# ATSAM4LS8C device description
Architecture: CORTEX-M4; Family: SAM4; Series: SAM4L
Registers are 32-bit, read-write, reset 0x0 unless marked. A register's access mark holds for its fields unless they carry their own. Offsets are from the block's base; [hi:lo] are bit positions; {n}, {i} and the like mark numbered series; 'fields as' and 'values as' point back to an identical list.

## CHIPID — Chip ID Registers
Instances: CHIPID 0x400E0400
0x340 CIDR ro reset 0xAB0B0AE0 — Chip ID Register
0x344 EXID ro reset 0x14000002 — Chip ID Extension Register

## CRCCU — CRC Calculation Unit
Instances: CRCCU 0x400A4000
0x00 DSCR — Descriptor Base Register
  [31:9] DSCR — Description Base Address
0x08 DMAEN wo (atomic set of DMASR) — DMA Enable Register
  [0] DMAEN — DMA Enable
0x0C DMADIS wo (atomic clear of DMASR) — DMA Disable Register
  [0] DMADIS — DMA Disable
0x10 DMASR ro — DMA Status Register
  [0] DMASR — DMA Channel Status
0x14 DMAIER wo (atomic set of DMAIMR) — DMA Interrupt Enable Register
  [0] DMAIER — DMA Interrupt Enable
0x18 DMAIDR wo (atomic clear of DMAIMR) — DMA Interrupt Disable Register
  [0] DMAIDR — DMA Interrupt Disable
0x1C DMAIMR ro — DMA Interrupt Mask Register
  [0] DMAIMR — DMA Interrupt Mask
0x20 DMAISR ro — DMA Interrupt Status Register
  [0] DMAISR — DMA Interrupt Status
0x34 CR wo — Control Register
  [0] RESET — Reset CRCComputation
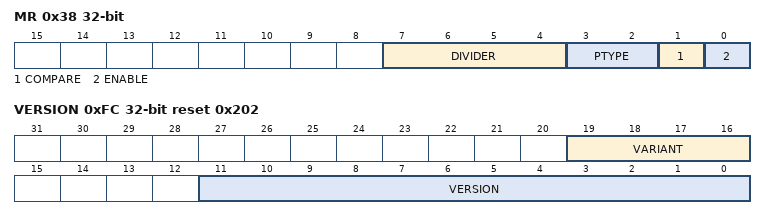
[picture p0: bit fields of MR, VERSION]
0x38 MR — Mode Register
  [7:4] DIVIDER — Bandwidth Divider
  [3:2] PTYPE — Polynomial Type
    0=CCITT8023; 1=CASTAGNOLI; 2=CCITT16
  [1] COMPARE — CRC Compare
  [0] ENABLE — CRC Computation Enable
0x3C SR ro reset 0xFFFFFFFF — Status Register
  [31:0] CRC — Cyclic Redundancy Check Value
0x40 IER wo (atomic set of IMR) — Interrupt Enable Register
  [0] ERRIER — CRC Error Interrupt Enable
0x44 IDR wo (atomic clear of IMR) — Interrupt Disable Register
  [0] ERRIDR — CRC Error Interrupt Disable
0x48 IMR ro — Interrupt Mask Register
  [0] ERRIMR — CRC Error Interrupt Mask
0x4C ISR ro — Interrupt Status Register
  [0] ERRISR — CRC Error Interrupt Status
0xFC VERSION ro reset 0x202
  [19:16] VARIANT — Variant Number
  [11:0] VERSION — Version Number

## DACC — DAC Controller
Instances: DACC 0x4003C000
0x00 CR wo — Control Register
  [0] SWRST — Software Reset
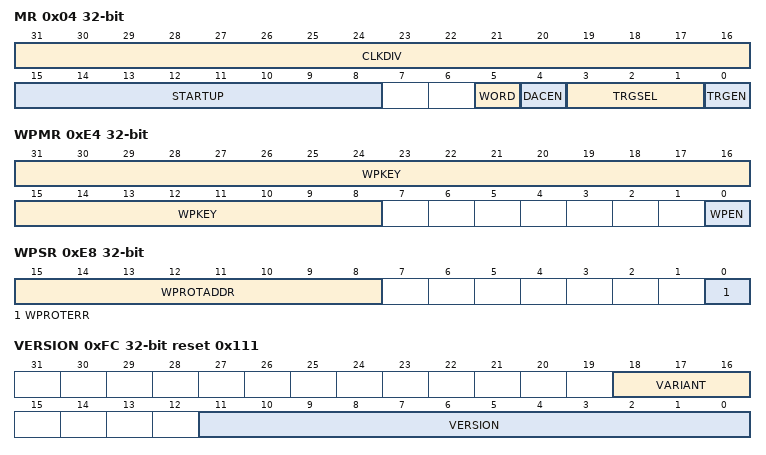
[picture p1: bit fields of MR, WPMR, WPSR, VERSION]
0x04 MR — Mode Register
  [31:16] CLKDIV — Clock Divider for Internal Trigger
  [15:8] STARTUP — Startup Time Selection
  [5] WORD — Word Transfer
  [4] DACEN — DAC Enable
  [3:1] TRGSEL — Trigger Selection
  [0] TRGEN — Trigger Enable
0x08 CDR wo — Conversion Data Register
  [31:0] DATA — Data to Convert
0x0C IER wo (atomic set of IMR) — Interrupt Enable Register
  [0] TXRDY — Transmit Ready Interrupt Enable
0x10 IDR wo reset not defined (atomic clear of IMR) — Interrupt Disable Register
  [0] TXRDY — Transmit Ready Interrupt Disable
0x14 IMR ro — Interrupt Mask Register
  [0] TXRDY — Transmit Ready Interrupt Mask
0x18 ISR ro — Interrupt Status Register
  [0] TXRDY — Transmit Ready Interrupt Status
0xE4 WPMR — Write Protect Mode Register
  [31:8] WPKEY — Write Protect Key
  [0] WPEN — Write Protect Enable
0xE8 WPSR ro — Write Protect Status Register
  [15:8] WPROTADDR — Write Protection Error Address
  [0] WPROTERR — Write Protection Error
0xFC VERSION ro reset 0x111
  [18:16] VARIANT — Variant Number
  [11:0] VERSION — Version Number

## EIC — External Interrupt Controller
Instances: EIC 0x400F1000
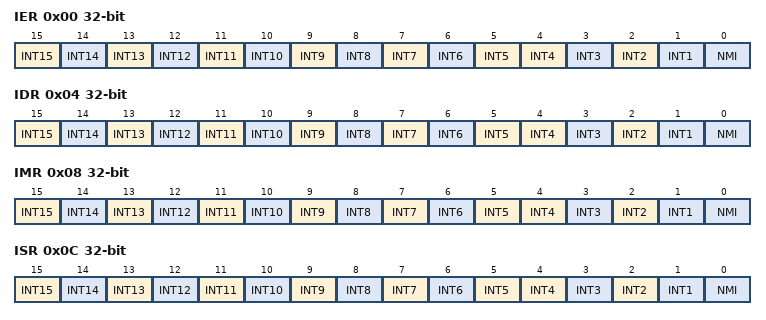
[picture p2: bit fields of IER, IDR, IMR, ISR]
0x00 IER wo (atomic set of IMR) — Interrupt Enable Register
  [n] INT{n} (n=5..15) — External Interrupt {n}
  [n] INT{n} (n=1..4) — External Interrupt {n}
    0=No effect; 1=Enable Interrupt
  [0] NMI — External Non Maskable CPU interrupt
0x04 IDR wo (atomic clear of IMR) — Interrupt Disable Register
  [n] INT{n} (n=5..15) — External Interrupt {n}
  [n] INT{n} (n=1..4) — External Interrupt {n}
    0=No effect; 1=Disable Interrupt
  [0] NMI — External Non Maskable CPU interrupt
0x08 IMR ro — Interrupt Mask Register
  [n] INT{n} (n=5..15) — External Interrupt {n}
  [n] INT{n} (n=1..4) — External Interrupt {n}
    0=Interrupt is disabled; 1=Interrupt is enabled
  [0] NMI — External Non Maskable CPU interrupt
0x0C ISR ro — Interrupt Status Register
  [n] INT{n} (n=5..15) — External Interrupt {n}
  [n] INT{n} (n=1..4) — External Interrupt {n}
    0=An interrupt event has not occurred; 1=An interrupt event has occurred
  [0] NMI — External Non Maskable CPU interrupt
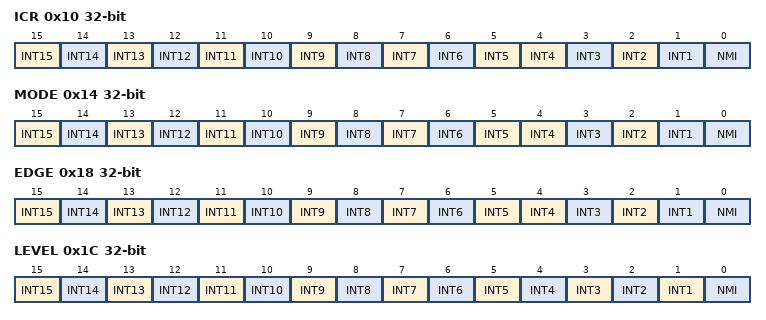
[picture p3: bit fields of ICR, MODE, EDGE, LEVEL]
0x10 ICR wo (atomic clear of ISR) — Interrupt Clear Register
  [n] INT{n} (n=5..15) — External Interrupt {n}
  [n] INT{n} (n=1..4) — External Interrupt {n}
    0=No effect; 1=Clear Interrupt
  [0] NMI — External Non Maskable CPU interrupt
0x14 MODE
  [n] INT{n} (n=5..15) — External Interrupt {n}
  [n] INT{n} (n=1..4) — External Interrupt {n}
    0=Edge triggered interrupt; 1=Level triggered interrupt
  [0] NMI — External Non Maskable CPU interrupt
0x18 EDGE
  [n] INT{n} (n=5..15) — External Interrupt {n}
  [n] INT{n} (n=1..4) — External Interrupt {n}
    0=Triggers on falling edge; 1=Triggers on rising edge
  [0] NMI — External Non Maskable CPU interrupt
0x1C LEVEL
  [n] INT{n} (n=1..15) — External Interrupt {n}
  [0] NMI — External Non Maskable CPU interrupt
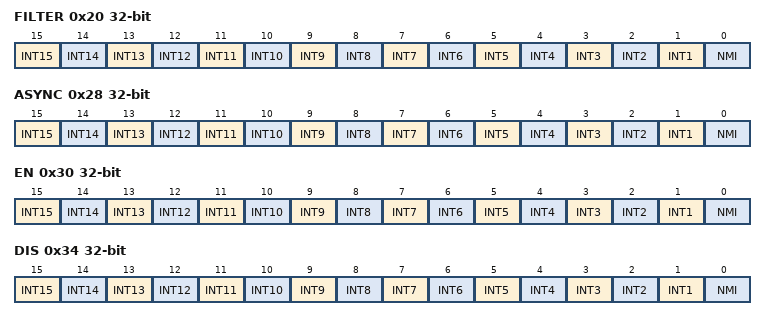
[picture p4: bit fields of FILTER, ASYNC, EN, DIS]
0x20 FILTER
  fields as LEVEL
0x28 ASYNC — Asynchronous Register
  fields as LEVEL
0x30 EN wo (atomic set of CTRL) — Enable Register
  fields as LEVEL
0x34 DIS wo (atomic clear of CTRL) — Disable Register
  fields as LEVEL
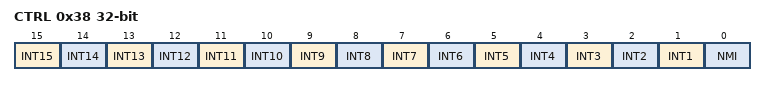
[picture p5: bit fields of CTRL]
0x38 CTRL ro — Control Register
  fields as LEVEL
0x3FC VERSION ro reset 0x302
  [11:0] VERSION — Version bits

## Notices in the file
Copyright (c) 2016 Atmel Corporation,
a wholly owned subsidiary of Microchip Technology Inc.
Licensed under the Apache License, Version 2.0 (the "License");
you may not use this file except in compliance with the License.
You may obtain a copy of the Licence at
http://www.apache.org/licenses/LICENSE-2.0
Unless required by applicable law or agreed to in writing, software
distributed under the License is distributed on an "AS IS" BASIS,
WITHOUT WARRANTIES OR CONDITIONS OF ANY KIND, either express or implied.
See the License for the specific language governing permissions and
limitations under the License.
